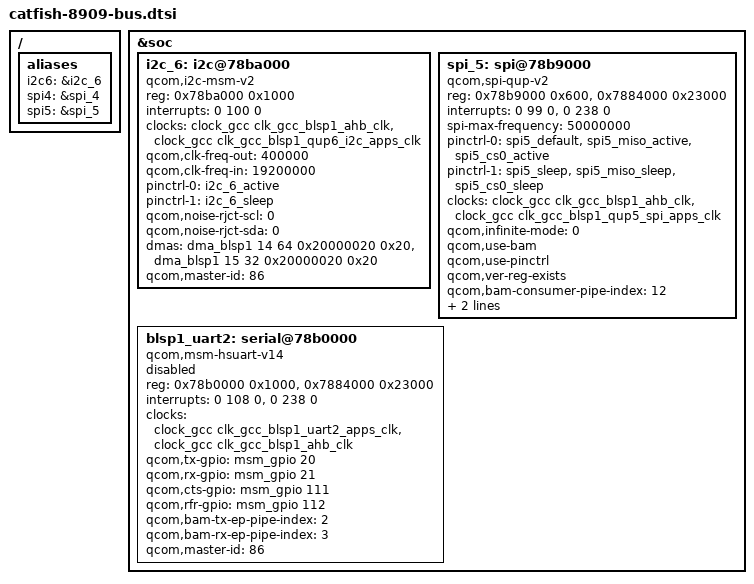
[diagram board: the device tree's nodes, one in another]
/*add catfish/catshark bus info*/
/ {
	aliases {
		/delete-property/ i2c2;
		/delete-property/ i2c3;
		/delete-property/ i2c4;
		/delete-property/ i2c5;
		/delete-property/ spi0;
		i2c6 = &i2c_6;
		spi4 = &spi_4;
		spi5 = &spi_5; /* SPI5 GPS controller device */
	};
};
&soc {
	i2c@78b8000 {
		/delete-node/ smb1357-charger@57;
		/delete-node/ smb358-charger@57;
	};
	i2c@78b9000 {
		/delete-node/ synaptics@20;
	};
	/delete-node/ spi@78ba000;
	/delete-node/ i2c@78b6000;
	/delete-node/ i2c@78b7000;
	/delete-node/ i2c@78b8000;
	/delete-node/ i2c@78b9000;

	i2c_6: i2c@78ba000 { /* BLSP1 QUP6 */
		compatible = "qcom,i2c-msm-v2";
		#address-cells = <1>;
		#size-cells = <0>;
		reg-names = "qup_phys_addr";
		reg = <0x78ba000 0x1000>;
		interrupt-names = "qup_irq";
		interrupts = <0 100 0>;
		clocks = <&clock_gcc clk_gcc_blsp1_ahb_clk>,
			<&clock_gcc clk_gcc_blsp1_qup6_i2c_apps_clk>;
		clock-names = "iface_clk", "core_clk";
		qcom,clk-freq-out = <400000>;
		qcom,clk-freq-in  = <19200000>;
		pinctrl-names = "i2c_active", "i2c_sleep";
		pinctrl-0 = <&i2c_6_active>;
		pinctrl-1 = <&i2c_6_sleep>;
		qcom,noise-rjct-scl = <0>;
		qcom,noise-rjct-sda = <0>;
		dmas = <&dma_blsp1 14 64 0x20000020 0x20>,
			<&dma_blsp1 15 32 0x20000020 0x20>;
		dma-names = "tx", "rx";
		qcom,master-id = <86>;
		status ="ok";
	};
	spi_5: spi@78b9000 { /* BLSP1 QUP5 */
		compatible = "qcom,spi-qup-v2";
		#address-cells = <1>;
		#size-cells = <0>;
		reg-names = "spi_physical", "spi_bam_physical";
		reg = <0x78b9000 0x600>,
			<0x7884000 0x23000>;
		interrupt-names = "spi_irq", "spi_bam_irq";
		interrupts = <0 99 0>, <0 238 0>;
		spi-max-frequency = <50000000>;
		pinctrl-names = "spi_default", "spi_sleep";
		pinctrl-0 = <&spi5_default &spi5_miso_active &spi5_cs0_active>;
		pinctrl-1 = <&spi5_sleep &spi5_miso_sleep &spi5_cs0_sleep>;
		clocks = <&clock_gcc clk_gcc_blsp1_ahb_clk>,
		<&clock_gcc clk_gcc_blsp1_qup5_spi_apps_clk>;
		clock-names = "iface_clk", "core_clk";
		qcom,infinite-mode = <0>;
		qcom,use-bam;
		qcom,use-pinctrl;
		qcom,ver-reg-exists;
		qcom,bam-consumer-pipe-index = <12>;
		qcom,bam-producer-pipe-index = <13>;
		qcom,master-id = <86>;
		status = "ok";
	};

	blsp1_uart2: serial@78b0000 {
		compatible = "qcom,msm-hsuart-v14";
		reg-names = "core_mem", "bam_mem";
		reg = <0x78b0000 0x1000>,
			<0x7884000 0x23000>;
		interrupt-names = "core_irq", "bam_irq";
		interrupts = <0 108 0>, <0 238 0>;
		status = "disabled";
		clocks = <&clock_gcc clk_gcc_blsp1_uart2_apps_clk>,
			<&clock_gcc clk_gcc_blsp1_ahb_clk>;
		clock-names = "core_clk", "iface_clk";
		qcom,tx-gpio = <&msm_gpio 20 0x00>;
		qcom,rx-gpio = <&msm_gpio 21 0x00>;
		qcom,cts-gpio = <&msm_gpio 111 0x00>;
		qcom,rfr-gpio = <&msm_gpio 112 0x00>;
		qcom,bam-tx-ep-pipe-index = <2>;
		qcom,bam-rx-ep-pipe-index = <3>;
		qcom,master-id = <86>;
	};
};
